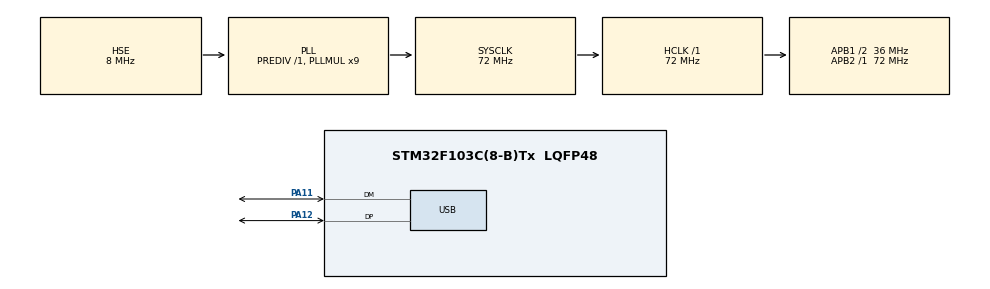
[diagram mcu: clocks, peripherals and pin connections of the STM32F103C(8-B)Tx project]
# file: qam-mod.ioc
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Mcu.Family=STM32F1
Mcu.Name=STM32F103C(8-B)Tx
Mcu.Package=LQFP48
NVIC.PriorityGroup=NVIC_PRIORITYGROUP_4
NVIC.USB_HP_CAN1_TX_IRQn=true\:0\:0\:false\:false\:true\:true\:true\:true
NVIC.USB_LP_CAN1_RX0_IRQn=true\:0\:0\:false\:false\:true\:true\:true\:true
PA11.Mode=Device
PA11.Signal=USB_DM
PA12.Mode=Device
PA12.Signal=USB_DP
PA13.Mode=Serial_Wire
PA13.Signal=SYS_JTMS-SWDIO
PA14.Mode=Serial_Wire
PA14.Signal=SYS_JTCK-SWCLK
PD0-OSC_IN.Mode=HSE-External-Oscillator
PD0-OSC_IN.Signal=RCC_OSC_IN
PD1-OSC_OUT.Mode=HSE-External-Oscillator
PD1-OSC_OUT.Signal=RCC_OSC_OUT
ProjectManager.HeapSize=0x200
ProjectManager.StackSize=0x400
ProjectManager.TargetToolchain=STM32CubeIDE
RCC.AHBFreq_Value=72000000
RCC.APB1CLKDivider=RCC_HCLK_DIV2
RCC.APB1Freq_Value=36000000
RCC.APB1TimFreq_Value=72000000
RCC.APB2Freq_Value=72000000
RCC.APB2TimFreq_Value=72000000
RCC.HCLKFreq_Value=72000000
RCC.PLLMUL=RCC_PLL_MUL9
RCC.SYSCLKFreq_VALUE=72000000
RCC.SYSCLKSource=RCC_SYSCLKSOURCE_PLLCLK
RCC.USBFreq_Value=48000000
RCC.USBPrescaler=RCC_USBCLKSOURCE_PLL_DIV1_5
USB_DEVICE.APP_RX_DATA_SIZE=256
USB_DEVICE.APP_TX_DATA_SIZE=256
USB_DEVICE.CLASS_NAME_FS=CDC
USB_DEVICE.CONFIGURATION_STRING_CDC_FS=QAM modulator controller
USB_DEVICE.INTERFACE_STRING_CDC_FS=QAM modulator controller
USB_DEVICE.MANUFACTURER_STRING=Piotr Wilkon
USB_DEVICE.PRODUCT_STRING_CDC_FS=QAM modulator controller
USB_DEVICE.USBD_MAX_STR_DESC_SIZ=64
USB_DEVICE.VirtualMode=Cdc
USB_DEVICE.VirtualModeFS=Cdc_FS
VP_USB_DEVICE_VS_USB_DEVICE_CDC_FS.Mode=CDC_FS
board=custom

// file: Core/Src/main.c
/* USER CODE BEGIN Header */
/**
  ******************************************************************************
  * @file           : main.c
  * @brief          : Main program body
  ******************************************************************************
  * @attention
  *
  * <h2><center>&copy; Copyright (c) 2023 STMicroelectronics.
  * All rights reserved.</center></h2>
  *
  * This software component is licensed by ST under BSD 3-Clause license,
  * the "License"; You may not use this file except in compliance with the
  * License. You may obtain a copy of the License at:
  *                        opensource.org/licenses/BSD-3-Clause
  *
  ******************************************************************************
  */

/*
Copyright 2023 Piotr Wilkon
This file is part of QAM Modulator Controller.

QAM Modulator Controller is free software: you can redistribute it and/or modify
it under the terms of the GNU General Public License as published by
the Free Software Foundation; either version 3 of the License, or
(at your option) any later version.

QAM Modulator Controller is distributed in the hope that it will be useful,
but WITHOUT ANY WARRANTY; without even the implied warranty of
MERCHANTABILITY or FITNESS FOR A PARTICULAR PURPOSE.  See the
GNU General Public License for more details.

You should have received a copy of the GNU General Public License
along with QAM Modulator Controller.  If not, see <http://www.gnu.org/licenses/>.
*/

/* USER CODE END Header */
#include "main.h"
#include "usb_device.h"

/* USER CODE BEGIN Includes */
#include "common.h"
#include "terminal.h"
#include "uart.h"
#include "modulator.h"
#include "audio.h"
/* USER CODE END Includes */

void SystemClock_Config(void);
static void MX_GPIO_Init(void);

int main(void)
{

  /* MCU Configuration--------------------------------------------------------*/

  /* Reset of all peripherals, Initializes the Flash interface and the Systick. */
  HAL_Init();

  /* Configure the system clock */
  SystemClock_Config();

  /* USER CODE BEGIN SysInit */

  	//USB pullup down when the peripheral is being initialized
	SET(RCC->APB2ENR, RCC_APB2ENR_IOPAEN);
	SET(GPIOA->CRH, GPIO_CRH_MODE15_1);
	RESET(GPIOA->CRH, GPIO_CRH_CNF15);
	GPIOA->BSRR = GPIO_BSRR_BR15;
	HAL_Delay(100);
	//USB pullup high to force enumeration
	GPIOA->BSRR = GPIO_BSRR_BS15;

  /* USER CODE END SysInit */

  /* Initialize all configured peripherals */
  MX_GPIO_Init();
  MX_USB_DEVICE_Init();
  /* USER CODE BEGIN 2 */

	UartInit(&UartUsb, NULL, 1);
	UartConfig(&UartUsb, 1);

	ModulatorInit();
	AudioInit();

  /* USER CODE END 2 */

  /* Infinite loop */
  while (1)
  {

    /* USER CODE BEGIN 3 */
	  if(UartUsb.rxType != DATA_NOTHING)
	  {
		  TermHandleSpecial(&UartUsb);
		  if(UartUsb.rxType != DATA_USB)
		  {
			  TermParse(&UartUsb);
		  	  UartClearRx(&UartUsb);
		  }
		  UartUsb.rxType = DATA_NOTHING;
	  }
	  if(Uart1.rxType != DATA_NOTHING)
	  {
		  TermParse(&Uart1);
		  UartClearRx(&Uart1);
	  }
	  if(Uart2.rxType != DATA_NOTHING)
	  {
		  TermParse(&Uart2);
		  UartClearRx(&Uart2);
	  }
  }
  /* USER CODE END 3 */
}

void SystemClock_Config(void)
{
  RCC_OscInitTypeDef RCC_OscInitStruct = {0};
  RCC_ClkInitTypeDef RCC_ClkInitStruct = {0};
  RCC_PeriphCLKInitTypeDef PeriphClkInit = {0};

  /** Initializes the RCC Oscillators according to the specified parameters
  * in the RCC_OscInitTypeDef structure.
  */
  RCC_OscInitStruct.OscillatorType = RCC_OSCILLATORTYPE_HSE;
  RCC_OscInitStruct.HSEState = RCC_HSE_ON;
  RCC_OscInitStruct.HSEPredivValue = RCC_HSE_PREDIV_DIV1;
  RCC_OscInitStruct.HSIState = RCC_HSI_ON;
  RCC_OscInitStruct.PLL.PLLState = RCC_PLL_ON;
  RCC_OscInitStruct.PLL.PLLSource = RCC_PLLSOURCE_HSE;
  RCC_OscInitStruct.PLL.PLLMUL = RCC_PLL_MUL9;
  if (HAL_RCC_OscConfig(&RCC_OscInitStruct) != HAL_OK)
  {
    Error_Handler();
  }

  /** Initializes the CPU, AHB and APB buses clocks
  */
  RCC_ClkInitStruct.ClockType = RCC_CLOCKTYPE_HCLK|RCC_CLOCKTYPE_SYSCLK
                              |RCC_CLOCKTYPE_PCLK1|RCC_CLOCKTYPE_PCLK2;
  RCC_ClkInitStruct.SYSCLKSource = RCC_SYSCLKSOURCE_PLLCLK;
  RCC_ClkInitStruct.AHBCLKDivider = RCC_SYSCLK_DIV1;
  RCC_ClkInitStruct.APB1CLKDivider = RCC_HCLK_DIV2;
  RCC_ClkInitStruct.APB2CLKDivider = RCC_HCLK_DIV1;

  if (HAL_RCC_ClockConfig(&RCC_ClkInitStruct, FLASH_LATENCY_2) != HAL_OK)
  {
    Error_Handler();
  }
  PeriphClkInit.PeriphClockSelection = RCC_PERIPHCLK_USB;
  PeriphClkInit.UsbClockSelection = RCC_USBCLKSOURCE_PLL_DIV1_5;
  if (HAL_RCCEx_PeriphCLKConfig(&PeriphClkInit) != HAL_OK)
  {
    Error_Handler();
  }
}

static void MX_GPIO_Init(void)
{

  /* GPIO Ports Clock Enable */
  __HAL_RCC_GPIOD_CLK_ENABLE();
  __HAL_RCC_GPIOA_CLK_ENABLE();

}

void Error_Handler(void)
{
  __disable_irq();
  while (1)
  {
  }
}
